# PIC32CX2051MTSH128S1 device description
Architecture: CORTEX-M4; Family: PIC32CXMT; Series: PIC32CXMTSH
Registers are 32-bit, read-write, no defined reset value unless marked. A register's access mark holds for its fields unless they carry their own. Offsets are from the block's base; [hi:lo] are bit positions; {n}, {i} and the like mark numbered series; 'fields as' and 'values as' point back to an identical list.

## PMC — Power Management Controller
Instances: PMC 0x46800000
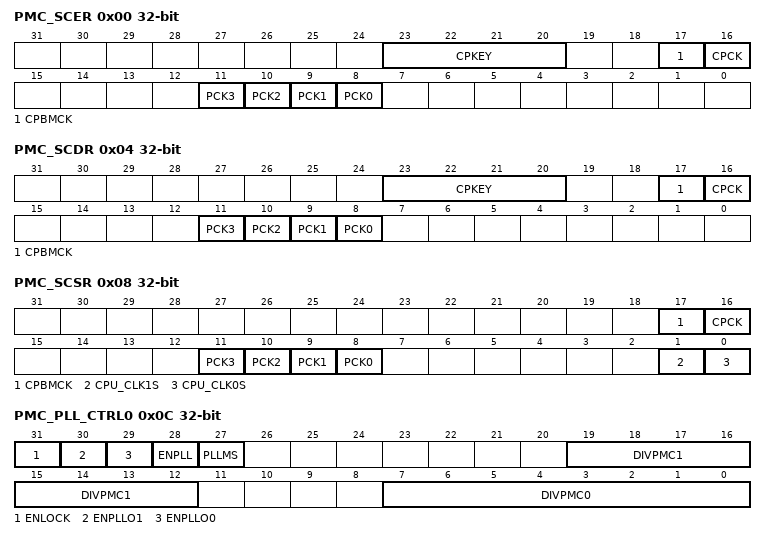
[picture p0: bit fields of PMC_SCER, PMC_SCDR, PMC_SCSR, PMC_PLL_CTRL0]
0x00 PMC_SCER wo — System Clock Enable Register
  [23:20] CPKEY — Coprocessor Clocks Enable Key
    10=PASSWD (This field must be written to 0xA to validate CPBMCK and CPCK.)
  [17] CPBMCK — Coprocessor Bus Master Clocks Enable
  [16] CPCK — Coprocessor (Second Processor) Clocks Enable
  [n+8] PCK{n} (n=0..3) — Programmable Clock {n} Output Enable
0x04 PMC_SCDR wo — System Clock Disable Register
  [23:20] CPKEY — Coprocessor Clocks Enable Key
    values as PMC_SCER.CPKEY
  [17] CPBMCK — Coprocessor Bus Master Clocks Disable
  [16] CPCK — Coprocessor (Second Processor) Clocks Disable
  [n+8] PCK{n} (n=0..3) — Programmable Clock {n} Output Disable
0x08 PMC_SCSR ro — System Clock Status Register
  [17] CPBMCK — Coprocessor Bus Master Clocks Status
  [16] CPCK — Coprocessor (Second Processor) Clocks Status
  [n+8] PCK{n} (n=0..3) — Programmable Clock {n} Output Status
  [1] CPU_CLK1S — CPU_CLK Status for Core 1
  [0] CPU_CLK0S — CPU_CLK Status for Core 0
0x0C PMC_PLL_CTRL0 — PLL Control Register 0
  [31] ENLOCK — Enable PLL Lock
  [30] ENPLLO1 — Enable PLL Clock Output 1 (PLLA only)
  [29] ENPLLO0 — Enable PLL Clock Output 0
  [28] ENPLL — Enable PLL
  [27] PLLMS — PLL Multiplexer Select
  [19:12] DIVPMC1 — Divider for PMC output 1 (PLLA only)
  [7:0] DIVPMC0 — Divider for PMC output 0
0x10 PMC_PLL_CTRL1 — PLL Control Register 1
  [15:0] MUL — Multiplier Factor Value for PLLA, B and C
0x14 PMC_PLL_CTRL2 — PLL Control Register 2
  [21:0] FRACR — Fractional Loop Divider Setting
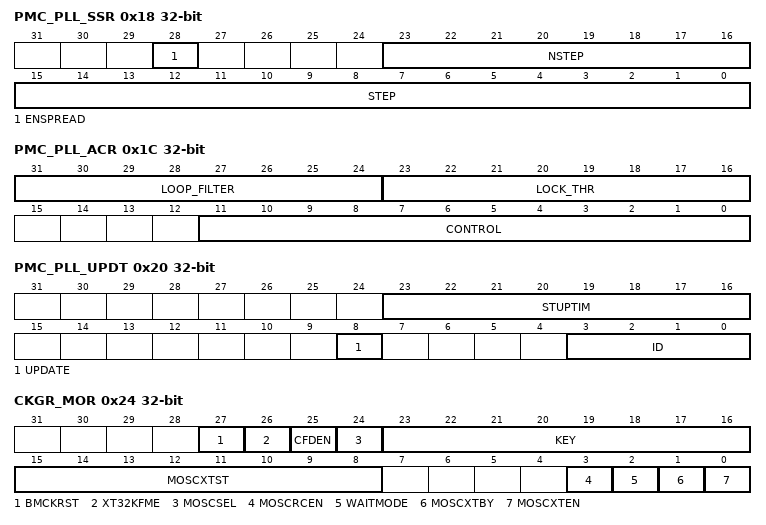
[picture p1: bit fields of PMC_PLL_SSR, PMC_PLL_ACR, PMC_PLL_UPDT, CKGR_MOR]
0x18 PMC_PLL_SSR — PLL Spread Spectrum Register
  [28] ENSPREAD — Spread Spectrum Enable
  [23:16] NSTEP — Spread Spectrum Number of Step
  [15:0] STEP — Spread Spectrum Step Size
0x1C PMC_PLL_ACR — PLL Analog Control Register
  [31:24] LOOP_FILTER — PLL Loop Filter Selection
  [23:16] LOCK_THR — PLL Lock Threshold Value Selection
  [11:0] CONTROL — PLL Control Value Selection
0x20 PMC_PLL_UPDT — PLL Update Register
  [23:16] STUPTIM — Start-up Time
  [8] UPDATE — PLL Setting Update (write-only)
  [3:0] ID — PLL ID
0x24 CKGR_MOR — Main Oscillator Register
  [27] BMCKRST — Bad MCK0 Clock Reset Enable
  [26] XT32KFME — 32.768 kHz Crystal Oscillator Frequency Monitoring Enable
  [25] CFDEN — Clock Failure Detector Enable
  [24] MOSCSEL — Main Clock Oscillator Selection
    0=RC (The main RC oscillator is selected.); 1=XT (The main crystal oscillator is selected.)
  [23:16] KEY — Write Access Password
    55=PASSWD (Writing any other value in this field aborts the write operation. Always reads as 0.)
  [15:8] MOSCXTST — Main Crystal Oscillator Start-up Time
  [3] MOSCRCEN — Main RC Oscillator Enable
  [2] WAITMODE — Wait Mode Command (write-only)
  [1] MOSCXTBY — 12 to 48 MHz Crystal Oscillator Bypass
  [0] MOSCXTEN — Main Crystal Oscillator Enable
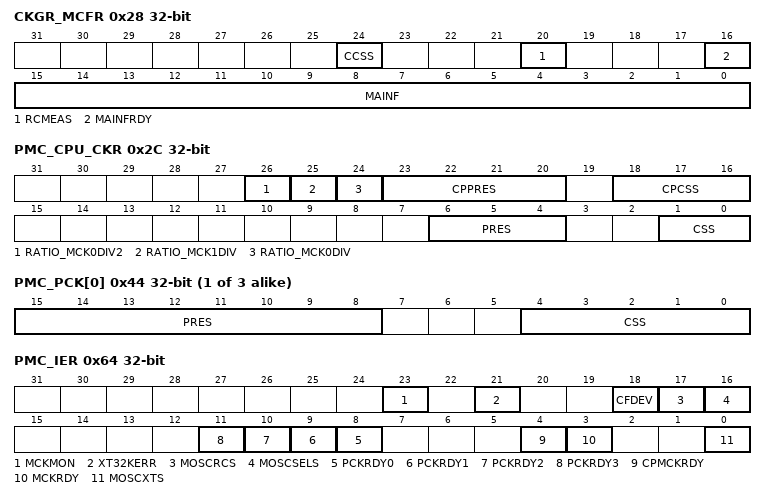
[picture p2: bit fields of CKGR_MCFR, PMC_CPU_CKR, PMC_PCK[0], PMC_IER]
0x28 CKGR_MCFR — Main Clock Frequency Register
  [24] CCSS — Counter Clock Source Selection
  [20] RCMEAS — RC Oscillator Frequency Measure (write-only)
  [16] MAINFRDY — Main Clock Frequency Measure Ready
  [15:0] MAINF — Main Clock Frequency
0x2C PMC_CPU_CKR — CPU Clock Register
  [26] RATIO_MCK0DIV2 — MCK0 Clock Frequency Division for MCK0DIV2 Clock
  [25] RATIO_MCK1DIV — MCK1 Clock Frequency Division for MCK1DIV Clock
  [24] RATIO_MCK0DIV — MCK0 Clock Frequency Division for MCK0DIV Clock
  [23:20] CPPRES — Coprocessor MCK1 Prescaler
    0=CLK_1 (Selected clock); {v}=CLK_{v+1} (Selected clock divided by {v+1}) (v=1..15)
  [18:16] CPCSS — Coprocessor MCK1 Source Selection
    0=MD_SLOW_CLK (MD_SLCK is selected); 1=MAINCK (MAINCK is selected); 2=MCK0 (MCK0 is selected); 3=PLLACK1 (PLLACK1 is selected); 4=PLLBCK (PLLBCK is selected); 5=PLLCCK (PLLCCK is selected)
  [6:4] PRES — Processor (CPU_CLK0) and Master Clock (MCK0) Prescaler
    0=CLK_1 (Selected clock); 1=CLK_2 (Selected clock divided by 2); 2=CLK_4 (Selected clock divided by 4); 3=CLK_8 (Selected clock divided by 8); 4=CLK_16 (Selected clock divided by 16); 5=CLK_32 (Selected clock divided by 32); 6=CLK_64 (Selected clock divided by 64); 7=CLK_3 (Selected clock divided by 3)
  [1:0] CSS — Processor (CPU_CLK0) and Master Clock (MCK0) Source Selection
    0=MD_SLOW_CLK (MD_SLCK is selected); 1=MAINCK (MAINCK is selected); 2=PLLACK1 (PLLACK1 is selected); 3=PLLBCK (PLLBCK is selected)
{0x44+4i} PMC_PCK[{i}] (i=0..2) — Programmable Clock Register (chid = 0)
  [15:8] PRES — Programmable Clock Prescaler
  [4:0] CSS — Programmable Clock Source Selection
    0=MD_SLOW_CLK (MD_SLCK is selected); 1=TD_SLOW_CLOCK (TD_SLCK is selected); 2=MAINCK (MAINCK is selected); 3=MCK0 (MCK0 is selected); 4=PLLACK1 (PLLACK1 is selected.); 5=PLLBCK (PLLBCK is selected.); 6=PLLCCK (PLLCCK is selected.); 7=PLLCSRC (PLLCSRC is selected.)
0x64 PMC_IER wo — Interrupt Enable Register
  [23] MCKMON — Master Clock 0 Clock Monitor Interrupt Enable
  [21] XT32KERR — 32.768 kHz Crystal Oscillator Error Interrupt Enable
  [18] CFDEV — Clock Failure Detector Event Interrupt Enable
  [17] MOSCRCS — Main RC Oscillator Status Interrupt Enable
  [16] MOSCSELS — Main Clock Source Oscillator Selection Status Interrupt Enable
  [n+8] PCKRDY{n} (n=0..3) — Programmable Clock Ready {n} Interrupt Enable
  [4] CPMCKRDY — Coprocessor Master Clock Ready Interrupt Enable
  [3] MCKRDY — Master Clock 0 Ready Interrupt Enable
  [0] MOSCXTS — Main Crystal Oscillator Status Interrupt Enable
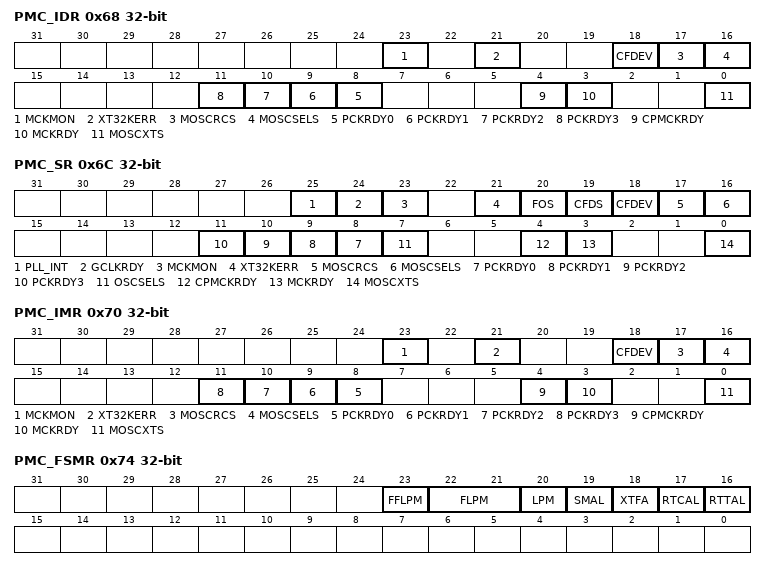
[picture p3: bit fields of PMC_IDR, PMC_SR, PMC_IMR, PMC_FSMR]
0x68 PMC_IDR wo — Interrupt Disable Register
  [23] MCKMON — Master Clock 0 Clock Monitor Interrupt Disable
  [21] XT32KERR — 32.768 kHz Crystal Oscillator Error Interrupt Disable
  [18] CFDEV — Clock Failure Detector Event Interrupt Disable
  [17] MOSCRCS — Main RC Status Interrupt Disable
  [16] MOSCSELS — Main Clock Source Oscillator Selection Status Interrupt Disable
  [n+8] PCKRDY{n} (n=0..3) — Programmable Clock Ready {n} Interrupt DIsable
  [4] CPMCKRDY — Coprocessor Master Clock Ready Interrupt Disable
  [3] MCKRDY — Master Clock 0 Ready Interrupt Disable
  [0] MOSCXTS — Main Crystal Oscillator Status Interrupt Disable
0x6C PMC_SR ro — Status Register
  [25] PLL_INT — PLL Interrupt Status
  [24] GCLKRDY — GCLK Ready
  [23] MCKMON — Master Clock 0 Clock Monitor Error
  [21] XT32KERR — Slow Crystal Oscillator Error
  [20] FOS — Clock Failure Detector Fault Output Status
  [19] CFDS — Clock Failure Detector Status
  [18] CFDEV — Clock Failure Detector Event
  [17] MOSCRCS — Main RC Oscillator Status
  [16] MOSCSELS — Main Clock Source Oscillator Selection Status
  [n+8] PCKRDY{n} (n=0..3) — Programmable Clock Ready Status
  [7] OSCSELS — Monitoring Domain Slow Clock Source Oscillator Selection
  [4] CPMCKRDY — Coprocessor Master Clock Status
  [3] MCKRDY — Master Clock 0 Status
  [0] MOSCXTS — Main Crystal Oscillator Status
0x70 PMC_IMR ro — Interrupt Mask Register
  [23] MCKMON — Master Clock 0 Monitor Error Interrupt Mask
  [21] XT32KERR — 32.768 kHz Crystal Oscillator Error Interrupt Mask
  [18] CFDEV — Clock Failure Detector Event Interrupt Mask
  [17] MOSCRCS — Main RC Status Interrupt Mask
  [16] MOSCSELS — Main Clock Source Oscillator Selection Status Interrupt Mask
  [n+8] PCKRDY{n} (n=0..3) — Programmable Clock Ready {n} Interrupt Mask
  [4] CPMCKRDY — Coprocessor Master Clock Ready Interrupt Mask
  [3] MCKRDY — Master Clock 0 Ready Interrupt Mask
  [0] MOSCXTS — Main Crystal Oscillator Status Interrupt Mask
0x74 PMC_FSMR — Fast Start-up Mode Register
  [23] FFLPM — Force Flash Low-power Mode
  [22:21] FLPM — Flash Low-power Mode
    0=FLASH_STANDBY (Flash is in Standby Mode when system enters Wait Mode); 1=FLASH_DEEP_POWERDOWN (Flash is in Deep-powerdown mode when system enters Wait Mode); 2=FLASH_IDLE (Idle mode)
  [20] LPM — Low Power Mode
  [19] SMAL — Supply Monitor Alarm Enable
  [18] XTFA — 32KHz Crystal Failure Alarm Enable
  [17] RTCAL — RTC Alarm Enable
  [16] RTTAL — RTT Alarm Enable
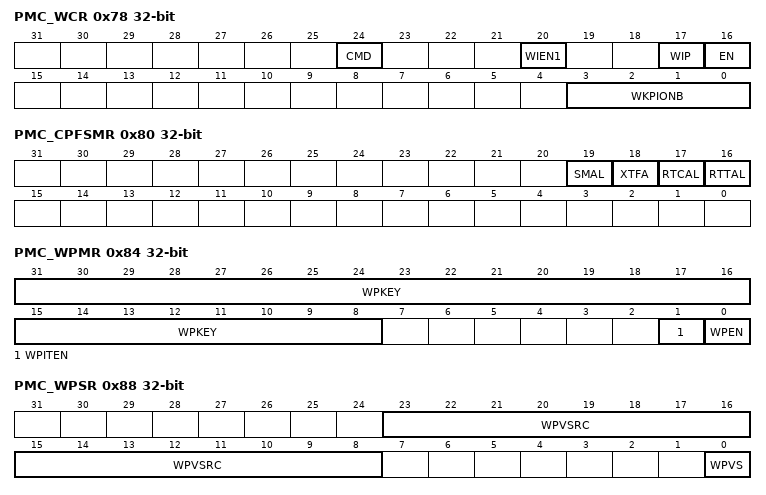
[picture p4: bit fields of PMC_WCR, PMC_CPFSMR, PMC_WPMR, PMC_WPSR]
0x78 PMC_WCR — Wake-up Control Register
  [24] CMD — Command
  [20] WIEN1 — Wake-up Input Enable 1
  [17] WIP — Wake-up Input Polarity
  [16] EN — Wake-up Input Enable
  [3:0] WKPIONB — Wake-up Input Number
0x7C PMC_FOCR wo — Fault Output Clear Register
  [0] FOCLR — Fault Output Clear
0x80 PMC_CPFSMR — Coprocessor Fast Start-up Mode Register
  [19] SMAL — Supply Monitor Alarm Enable
  [18] XTFA — 32KHz Crystal Failure Alarm Enable
  [17] RTCAL — RTC Alarm Enable
  [16] RTTAL — RTT Alarm Enable
0x84 PMC_WPMR — Write Protection Mode Register
  [31:8] WPKEY — Write Protection Key
    0x504D43=PASSWD (Writing any other value in this field aborts the write operation of the WPEN bit. Always reads as 0.)
  [1] WPITEN — Write Protection Interrupt Enable
  [0] WPEN — Write Protection Enable
0x88 PMC_WPSR ro — Write Protection Status Register
  [23:8] WPVSRC — Write Protection Violation Source
  [0] WPVS — Write Protection Violation Status
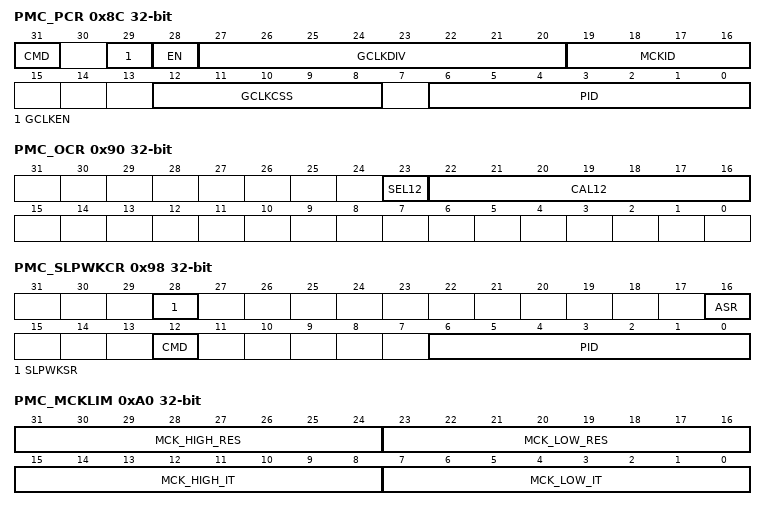
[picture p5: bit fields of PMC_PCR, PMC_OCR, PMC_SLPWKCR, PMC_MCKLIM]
0x8C PMC_PCR — Peripheral Control Register
  [31] CMD — Command
  [29] GCLKEN — Generic Clock Enable
  [28] EN — Enable
  [27:20] GCLKDIV — Generic Clock Division Ratio
  [19:16] MCKID — Master Clock Index (Read-only)
  [12:8] GCLKCSS — Generic Clock Source Selection
    values as PMC_PCK[0].CSS
  [6:0] PID — Peripheral ID
0x90 PMC_OCR — Oscillator Calibration Register
  [23] SEL12 — Selection of Main RC Oscillator Calibration Bits
  [22:16] CAL12 — Main RC Oscillator Calibration Bits
0x94 PMC_SLPWK_AIPR ro — Partial Wake-up Activity In Progress Register
  [0] AIP — Activity In Progress
0x98 PMC_SLPWKCR — Partial Wake-up Control Register
  [28] SLPWKSR — Partial Wake-up Sleep Register
  [16] ASR — Activity Status Register
  [12] CMD — Command
  [6:0] PID — Peripheral ID
0xA0 PMC_MCKLIM — MCK0 Monitor Limits Register
  [31:24] MCK_HIGH_RES — MCK0 Monitoring High Reset Limit
  [23:16] MCK_LOW_RES — MCK0 Monitoring Low RESET Limit
  [15:8] MCK_HIGH_IT — MCK0 Monitoring High IT Limit
  [7:0] MCK_LOW_IT — MCK0 Monitoring Low IT Limit
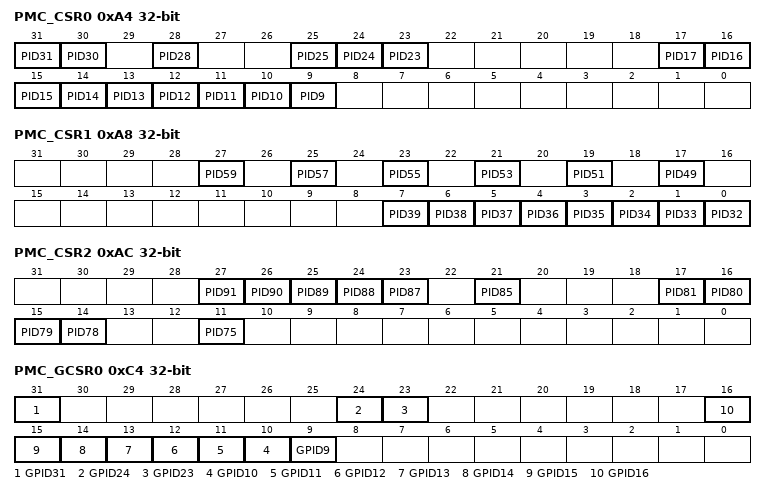
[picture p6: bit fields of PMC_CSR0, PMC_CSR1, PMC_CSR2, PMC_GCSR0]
0xA4 PMC_CSR0 ro — Peripheral Clock Status Register 0
  [31] PID31 — Peripheral Clock 31 Status
  [30] PID30 — Peripheral Clock 30 Status
  [28] PID28 — Peripheral Clock 28 Status
  [25] PID25 — Peripheral Clock 25 Status
  [24] PID24 — Peripheral Clock 24 Status
  [23] PID23 — Peripheral Clock 23 Status
  [n] PID{n} (n=9..17) — Peripheral Clock {n} Status
0xA8 PMC_CSR1 ro — Peripheral Clock Status Register 1
  [27] PID59 — Peripheral Clock 59 Status
  [25] PID57 — Peripheral Clock 57 Status
  [23] PID55 — Peripheral Clock 55 Status
  [21] PID53 — Peripheral Clock 53 Status
  [19] PID51 — Peripheral Clock 51 Status
  [17] PID49 — Peripheral Clock 49 Status
  [n-32] PID{n} (n=32..39) — Peripheral Clock {n} Status
0xAC PMC_CSR2 ro — Peripheral Clock Status Register 2
  [n-64] PID{n} (n=87..91) — Peripheral Clock {n} Status
  [21] PID85 — Peripheral Clock 85 Status
  [n-64] PID{n} (n=78..81) — Peripheral Clock {n} Status
  [11] PID75 — Peripheral Clock 75 Status
0xB0 PMC_CSR3 ro — Peripheral Clock Status Register 3
  [0] PID96 — Peripheral Clock 96 Status
0xC4 PMC_GCSR0 ro — Generic Clock Status Register 0
  [31] GPID31 — Generic Clock 31 Status
  [24] GPID24 — Generic Clock 24 Status
  [23] GPID23 — Generic Clock 23 Status
  [n] GPID{n} (n=9..16) — Generic Clock {n} Status
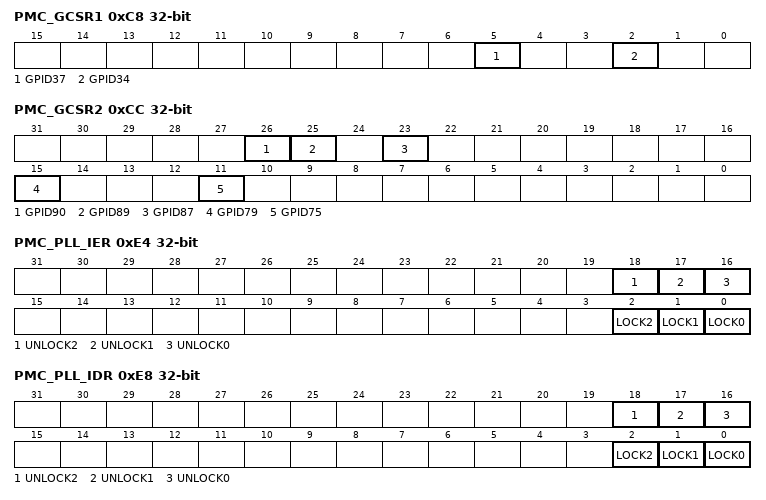
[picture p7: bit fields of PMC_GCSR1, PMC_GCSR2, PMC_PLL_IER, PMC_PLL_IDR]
0xC8 PMC_GCSR1 ro — Generic Clock Status Register 1
  [5] GPID37 — Generic Clock 37 Status
  [2] GPID34 — Generic Clock 34 Status
0xCC PMC_GCSR2 ro — Generic Clock Status Register 2
  [26] GPID90 — Generic Clock 90 Status
  [25] GPID89 — Generic Clock 89 Status
  [23] GPID87 — Generic Clock 87 Status
  [15] GPID79 — Generic Clock 79 Status
  [11] GPID75 — Generic Clock 75 Status
0xD0 PMC_GCSR3 ro — Generic Clock Status Register 3
  [0] GPID96 — Generic Clock 96 Status
0xE4 PMC_PLL_IER wo — PLL Interrupt Enable Register
  [18] UNLOCK2 — PLL of Index 2 Unlock Interrupt Enable
  [17] UNLOCK1 — PLL of Index 1 Unlock Interrupt Enable
  [16] UNLOCK0 — PLL of Index 0 Unlock Interrupt Enable
  [2] LOCK2 — PLL of Index 2 Lock Interrupt Enable
  [1] LOCK1 — PLL of Index 1 Lock Interrupt Enable
  [0] LOCK0 — PLL of Index 0 Lock Interrupt Enable
0xE8 PMC_PLL_IDR wo — PLL Interrupt Disable Register
  [18] UNLOCK2 — PLL of Index 2 Unlock Interrupt Disable
  [17] UNLOCK1 — PLL of Index 1 Unlock Interrupt Disable
  [16] UNLOCK0 — PLL of Index 0 Unlock Interrupt Disable
  [2] LOCK2 — PLL of Index 2 Lock Interrupt Disable
  [1] LOCK1 — PLL of Index 1 Lock Interrupt Disable
  [0] LOCK0 — PLL of Index 0 Lock Interrupt Disable
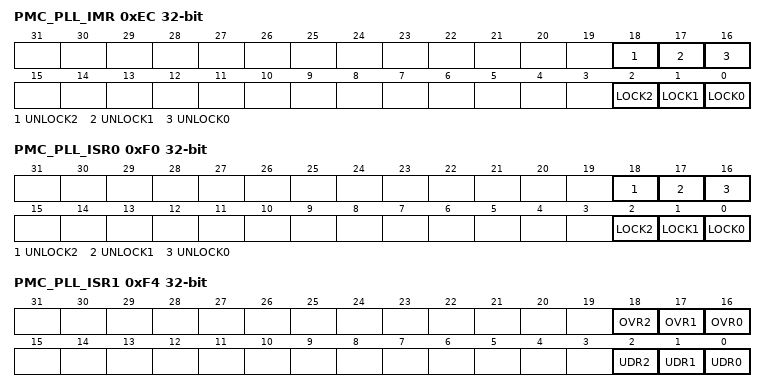
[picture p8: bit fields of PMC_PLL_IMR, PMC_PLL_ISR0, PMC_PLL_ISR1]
0xEC PMC_PLL_IMR ro — PLL Interrupt Mask Register
  [18] UNLOCK2 — PLL of Index 2 Unlock Interrupt Mask
  [17] UNLOCK1 — PLL of Index 1 Unlock Interrupt Mask
  [16] UNLOCK0 — PLL of Index 0 Unlock Interrupt Mask
  [2] LOCK2 — PLL of Index 2 Lock Interrupt Mask
  [1] LOCK1 — PLL of Index 1 Lock Interrupt Mask
  [0] LOCK0 — PLL of Index 0 Lock Interrupt Mask
0xF0 PMC_PLL_ISR0 ro — PLL Interrupt Status Register 0
  [18] UNLOCK2 — PLL of Index 2 Unlock Interrupt Status
  [17] UNLOCK1 — PLL of Index 1 Unlock Interrupt Status
  [16] UNLOCK0 — PLL of Index 0 Unlock Interrupt Status
  [2] LOCK2 — PLL of Index 2 Lock Interrupt Status
  [1] LOCK1 — PLL of Index 1 Lock Interrupt Status
  [0] LOCK0 — PLL of Index 0 Lock Interrupt Status
0xF4 PMC_PLL_ISR1 ro — PLL Interrupt Status Register 1
  [18] OVR2 — PLLx Overflow
  [17] OVR1 — PLLx Overflow
  [16] OVR0 — PLLx Overflow
  [2] UDR2 — PLLx Underflow
  [1] UDR1 — PLLx Underflow
  [0] UDR0 — PLLx Underflow

## Notices in the file
Copyright %copyright_year% Microchip Technology Inc.
SPDX-License-Identifier: Apache-2.0
Licensed under the Apache License, Version 2.0 (the "License");
you may not use this file except in compliance with the License.
You may obtain a copy of the License at
http://www.apache.org/licenses/LICENSE-2.0
Unless required by applicable law or agreed to in writing, software
distributed under the License is distributed on an "AS IS" BASIS,
WITHOUT WARRANTIES OR CONDITIONS OF ANY KIND, either express or implied.
See the License for the specific language governing permissions and
limitations under the License.
